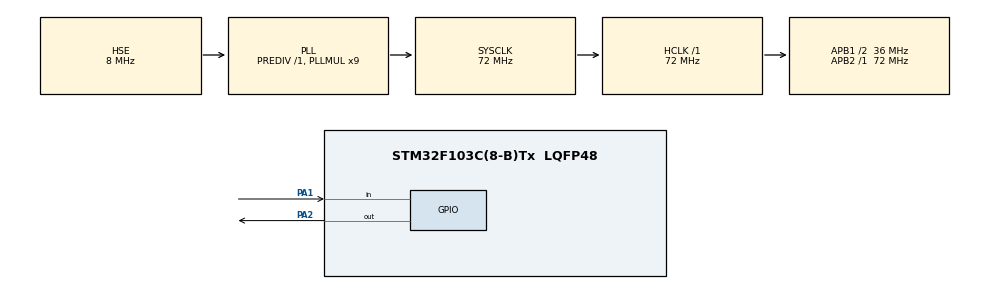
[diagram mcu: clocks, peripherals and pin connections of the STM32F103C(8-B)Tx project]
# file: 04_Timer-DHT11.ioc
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Mcu.Family=STM32F1
Mcu.Name=STM32F103C(8-B)Tx
Mcu.Package=LQFP48
NVIC.PriorityGroup=NVIC_PRIORITYGROUP_4
PA1.Signal=GPIO_Input
PA13.Mode=Serial_Wire
PA13.Signal=SYS_JTMS-SWDIO
PA14.Mode=Serial_Wire
PA14.Signal=SYS_JTCK-SWCLK
PA2.Signal=GPIO_Output
PD0-OSC_IN.Mode=HSE-External-Oscillator
PD0-OSC_IN.Signal=RCC_OSC_IN
PD1-OSC_OUT.Mode=HSE-External-Oscillator
PD1-OSC_OUT.Signal=RCC_OSC_OUT
ProjectManager.HeapSize=0x200
ProjectManager.StackSize=0x400
ProjectManager.TargetToolchain=STM32CubeIDE
RCC.AHBFreq_Value=72000000
RCC.APB1CLKDivider=RCC_HCLK_DIV2
RCC.APB1Freq_Value=36000000
RCC.APB1TimFreq_Value=72000000
RCC.APB2Freq_Value=72000000
RCC.APB2TimFreq_Value=72000000
RCC.HCLKFreq_Value=72000000
RCC.PLLMUL=RCC_PLL_MUL9
RCC.PLLSourceVirtual=RCC_PLLSOURCE_HSE
RCC.SYSCLKFreq_VALUE=72000000
RCC.SYSCLKSource=RCC_SYSCLKSOURCE_PLLCLK
RCC.USBFreq_Value=72000000
TIM1.Prescaler=71
VP_TIM1_VS_ClockSourceINT.Mode=Internal
board=custom

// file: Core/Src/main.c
/* USER CODE BEGIN Header */
/**
  ******************************************************************************
  * @file           : main.c
  * @brief          : Main program body
  ******************************************************************************
  * @attention
  *
  * Copyright (c) 2026 STMicroelectronics.
  * All rights reserved.
  *
  * This software is licensed under terms that can be found in the LICENSE file
  * in the root directory of this software component.
  * If no LICENSE file comes with this software, it is provided AS-IS.
  *
  ******************************************************************************
  */
/* USER CODE END Header */
#include "main.h"

/* USER CODE BEGIN Includes */

#include "dht11.h"

/* USER CODE END Includes */

TIM_HandleTypeDef htim1;

/* USER CODE BEGIN PV */

uint8_t dht11_temperature = 0;
uint8_t dht11_humidity = 0;

/* USER CODE END PV */

void SystemClock_Config(void);
static void MX_GPIO_Init(void);
static void MX_TIM1_Init(void);

int main(void)
{

  /* MCU Configuration--------------------------------------------------------*/

  /* Reset of all peripherals, Initializes the Flash interface and the Systick. */
  HAL_Init();

  /* Configure the system clock */
  SystemClock_Config();

  /* Initialize all configured peripherals */
  MX_GPIO_Init();
  MX_TIM1_Init();

  /* Infinite loop */
  while (1)
  {

    /* USER CODE BEGIN 3 */

    DHT11_ReadData(GPIOA, GPIO_PIN_1, &dht11_temperature, &dht11_humidity);
    HAL_Delay(1000);
  }
  /* USER CODE END 3 */
}

void SystemClock_Config(void)
{
  RCC_OscInitTypeDef RCC_OscInitStruct = {0};
  RCC_ClkInitTypeDef RCC_ClkInitStruct = {0};

  /** Initializes the RCC Oscillators according to the specified parameters
  * in the RCC_OscInitTypeDef structure.
  */
  RCC_OscInitStruct.OscillatorType = RCC_OSCILLATORTYPE_HSE;
  RCC_OscInitStruct.HSEState = RCC_HSE_ON;
  RCC_OscInitStruct.HSEPredivValue = RCC_HSE_PREDIV_DIV1;
  RCC_OscInitStruct.HSIState = RCC_HSI_ON;
  RCC_OscInitStruct.PLL.PLLState = RCC_PLL_ON;
  RCC_OscInitStruct.PLL.PLLSource = RCC_PLLSOURCE_HSE;
  RCC_OscInitStruct.PLL.PLLMUL = RCC_PLL_MUL9;
  if (HAL_RCC_OscConfig(&RCC_OscInitStruct) != HAL_OK)
  {
    Error_Handler();
  }

  /** Initializes the CPU, AHB and APB buses clocks
  */
  RCC_ClkInitStruct.ClockType = RCC_CLOCKTYPE_HCLK|RCC_CLOCKTYPE_SYSCLK
                              |RCC_CLOCKTYPE_PCLK1|RCC_CLOCKTYPE_PCLK2;
  RCC_ClkInitStruct.SYSCLKSource = RCC_SYSCLKSOURCE_PLLCLK;
  RCC_ClkInitStruct.AHBCLKDivider = RCC_SYSCLK_DIV1;
  RCC_ClkInitStruct.APB1CLKDivider = RCC_HCLK_DIV2;
  RCC_ClkInitStruct.APB2CLKDivider = RCC_HCLK_DIV1;

  if (HAL_RCC_ClockConfig(&RCC_ClkInitStruct, FLASH_LATENCY_2) != HAL_OK)
  {
    Error_Handler();
  }
}

static void MX_TIM1_Init(void)
{

  TIM_ClockConfigTypeDef sClockSourceConfig = {0};
  TIM_MasterConfigTypeDef sMasterConfig = {0};

  htim1.Instance = TIM1;
  htim1.Init.Prescaler = 71;
  htim1.Init.CounterMode = TIM_COUNTERMODE_UP;
  htim1.Init.Period = 65535;
  htim1.Init.ClockDivision = TIM_CLOCKDIVISION_DIV1;
  htim1.Init.RepetitionCounter = 0;
  htim1.Init.AutoReloadPreload = TIM_AUTORELOAD_PRELOAD_DISABLE;
  if (HAL_TIM_Base_Init(&htim1) != HAL_OK)
  {
    Error_Handler();
  }
  sClockSourceConfig.ClockSource = TIM_CLOCKSOURCE_INTERNAL;
  if (HAL_TIM_ConfigClockSource(&htim1, &sClockSourceConfig) != HAL_OK)
  {
    Error_Handler();
  }
  sMasterConfig.MasterOutputTrigger = TIM_TRGO_RESET;
  sMasterConfig.MasterSlaveMode = TIM_MASTERSLAVEMODE_DISABLE;
  if (HAL_TIMEx_MasterConfigSynchronization(&htim1, &sMasterConfig) != HAL_OK)
  {
    Error_Handler();
  }

}

static void MX_GPIO_Init(void)
{
  GPIO_InitTypeDef GPIO_InitStruct = {0};

  /* GPIO Ports Clock Enable */
  __HAL_RCC_GPIOD_CLK_ENABLE();
  __HAL_RCC_GPIOA_CLK_ENABLE();

  /*Configure GPIO pin Output Level */
  HAL_GPIO_WritePin(GPIOA, GPIO_PIN_2, GPIO_PIN_RESET);

  /*Configure GPIO pin : PA1 */
  GPIO_InitStruct.Pin = GPIO_PIN_1;
  GPIO_InitStruct.Mode = GPIO_MODE_INPUT;
  GPIO_InitStruct.Pull = GPIO_PULLUP;
  HAL_GPIO_Init(GPIOA, &GPIO_InitStruct);

  /*Configure GPIO pin : PA2 */
  GPIO_InitStruct.Pin = GPIO_PIN_2;
  GPIO_InitStruct.Mode = GPIO_MODE_OUTPUT_PP;
  GPIO_InitStruct.Pull = GPIO_NOPULL;
  GPIO_InitStruct.Speed = GPIO_SPEED_FREQ_LOW;
  HAL_GPIO_Init(GPIOA, &GPIO_InitStruct);

}

void Error_Handler(void)
{
  __disable_irq();
  while (1)
  {
  }
}
